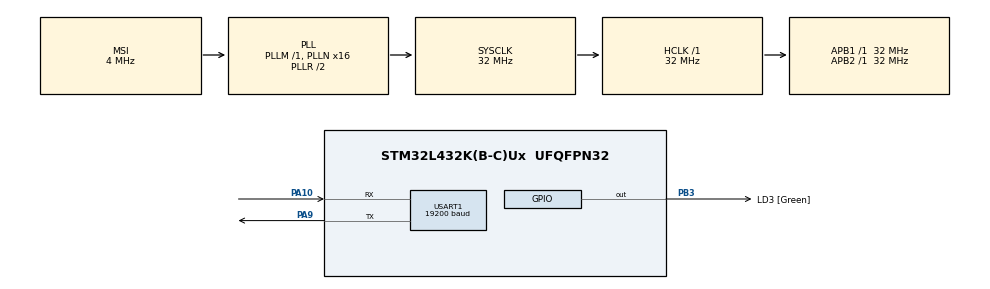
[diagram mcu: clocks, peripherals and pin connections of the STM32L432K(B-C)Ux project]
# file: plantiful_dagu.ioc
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Mcu.Family=STM32L4
Mcu.Name=STM32L432K(B-C)Ux
Mcu.Package=UFQFPN32
NVIC.PriorityGroup=NVIC_PRIORITYGROUP_4
PA0.GPIO_Label=MCO [High speed clock in]
PA0.Mode=HSE-External-Clock-Source-for-LittleOrca
PA0.Signal=RCC_CK_IN
PA10.Mode=Asynchronous
PA10.Signal=USART1_RX
PA13\ (JTMS-SWDIO).GPIO_Label=SWDIO
PA13\ (JTMS-SWDIO).Mode=Serial_Wire
PA13\ (JTMS-SWDIO).Signal=SYS_JTMS-SWDIO
PA14\ (JTCK-SWCLK).GPIO_Label=SWCLK
PA14\ (JTCK-SWCLK).Mode=Serial_Wire
PA14\ (JTCK-SWCLK).Signal=SYS_JTCK-SWCLK
PA15\ (JTDI).GPIO_Label=VCP_RX
PA15\ (JTDI).Signal=USART2_RX
PA2.GPIO_Label=VCP_TX
PA2.Signal=USART2_TX
PA9.Mode=Asynchronous
PA9.Signal=USART1_TX
PB3\ (JTDO-TRACESWO).GPIO_Label=LD3 [Green]
PB3\ (JTDO-TRACESWO).Signal=GPIO_Output
PC14-OSC32_IN\ (PC14).Mode=LSE-External-Oscillator
PC14-OSC32_IN\ (PC14).Signal=RCC_OSC32_IN
PC15-OSC32_OUT\ (PC15).Mode=LSE-External-Oscillator
PC15-OSC32_OUT\ (PC15).Signal=RCC_OSC32_OUT
ProjectManager.HeapSize=0x200
ProjectManager.StackSize=0x400
ProjectManager.TargetToolchain=MDK-ARM V5.27
RCC.AHBFreq_Value=32000000
RCC.APB1Freq_Value=32000000
RCC.APB1TimFreq_Value=32000000
RCC.APB2Freq_Value=32000000
RCC.APB2TimFreq_Value=32000000
RCC.CortexFreq_Value=32000000
RCC.HCLKFreq_Value=32000000
RCC.HSE_VALUE=8000000
RCC.HSI16_VALUE=16000000
RCC.HSI48_VALUE=48000000
RCC.HSI_VALUE=16000000
RCC.MSI_VALUE=4000000
RCC.PLLMUL=RCC_PLLMUL_4
RCC.PLLN=16
RCC.SYSCLKFreq_VALUE=32000000
RCC.SYSCLKSource=RCC_SYSCLKSOURCE_PLLCLK
RCC.VCOOutputFreq_Value=64000000
USART1.BaudRate=19200
USART1.VirtualMode-Asynchronous=VM_ASYNC
board=NUCLEO-L432KC

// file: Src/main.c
/* USER CODE BEGIN Header */
/**
  ******************************************************************************
  * @file           : main.c
  * @brief          : Main program body
  ******************************************************************************
  * @attention
  *
  * <h2><center>&copy; Copyright (c) 2021 STMicroelectronics.
  * All rights reserved.</center></h2>
  *
  * This software component is licensed by ST under BSD 3-Clause license,
  * the "License"; You may not use this file except in compliance with the
  * License. You may obtain a copy of the License at:
  *                        opensource.org/licenses/BSD-3-Clause
  *
  ******************************************************************************
  */
/* USER CODE END Header */

#include "main.h"

UART_HandleTypeDef huart1;

/* USER CODE BEGIN PV */
char buff[2];
int moveTime = 1000;
int stopTime = 50000;
/* USER CODE END PV */

void SystemClock_Config(void);
static void MX_GPIO_Init(void);
static void MX_USART1_UART_Init(void);

/* USER CODE BEGIN 0 */

void forward(void)
{
		/* Forward */
		buff[1] = 0x40; /* Set speed to be 50% of max (1.5 km/h) */
		buff[0] = 0xC2;
		HAL_UART_Transmit(&huart1, (uint8_t *) buff, sizeof(buff), 200);

		buff[1] = 0x40;
		buff[0] = 0xCA;
		HAL_UART_Transmit(&huart1, (uint8_t *) buff, sizeof(buff), 200);

		//HAL_Delay(500); /* Delay to move forward for a set time */
}

void backwards(void)
{
	  /*  Backwards */
		buff[1] = 0x40; /* Set speed to be 50% of max (1.5 km/h) */
		buff[0] = 0xC1;
		HAL_UART_Transmit(&huart1, (uint8_t *) buff, sizeof(buff), 200);

		buff[0] = 0xC9;
		HAL_UART_Transmit(&huart1, (uint8_t *) buff, sizeof(buff), 200);

		//HAL_Delay(500); /* Delay to move forward for a set time */
}

void right(void)
{
		/* Turn Right */
		buff[1] = 0x40;
		buff[0] = 0xC2;
		HAL_UART_Transmit(&huart1, (uint8_t *) buff, sizeof(buff), 200);

		//buff[1] = 0x06;
		//buff[0] = 0xCA;
		buff[1] = 0x40;
		buff[0] = 0xC9;
		HAL_UART_Transmit(&huart1, (uint8_t *) buff, sizeof(buff), 200);

		HAL_Delay(550); // we found that the left motor was weaker -> the same delay made it turn less degrees -> increase delay to account for weaker motor

}

void brake(void)
{
	  /* Brake */
		buff[1] = 0x00;
		buff[0] = 0xC0;
		HAL_UART_Transmit(&huart1, (uint8_t *) buff, sizeof(buff), 200);
		buff[0] = 0xC8;
		HAL_UART_Transmit(&huart1, (uint8_t *) buff, sizeof(buff), 200);

		HAL_Delay(5);

}

void turn(void)
{
	/* Turning right */

	buff[1] = 0x40; //50% power
	buff[0] = 0xC2;	//left wheel
	HAL_UART_Transmit(&huart1, (uint8_t *) buff, sizeof(buff), 200);

	buff[1] = 0x20;	//25% power
	buff[0] = 0xC9;	//right wheel
	HAL_UART_Transmit(&huart1, (uint8_t *) buff, sizeof(buff), 200);

	/* These seconds with these speeds, make it turn 180 degrees */
	HAL_Delay(1350);
	brake();

	/* Turning left
	buff[1] = 0x28;
	buff[0] = 0xC1;
	HAL_UART_Transmit(&huart1, (uint8_t *) buff, sizeof(buff), 200);

	buff[1] = 0x40;
	buff[0] = 0xCA;
	HAL_UART_Transmit(&huart1, (uint8_t *) buff, sizeof(buff), 200);

	HAL_Delay(900);*/
}

/* USER CODE END 0 */

int main(void)
{

  /* MCU Configuration--------------------------------------------------------*/

  /* Reset of all peripherals, Initializes the Flash interface and the Systick. */
  HAL_Init();

  /* Configure the system clock */
  SystemClock_Config();

  /* Initialize all configured peripherals */
  MX_GPIO_Init();
  MX_USART1_UART_Init();

  /* Infinite loop */
  while (1)
  {
    /* USER CODE BEGIN 3 */

		/* Capture plants for this day */
		for (int row = 0; row < 2; row++) {

			for(int plant = 0; plant < 5; plant++) {
				forward(); 									/* set car direction to forward */
				HAL_Delay(moveTime);				/* move car for time traveled between pots */
				brake();										/* stop car */
				HAL_Delay(stopTime);				/* pause car for capturing time */
			}

			turn();												/* turn to face the other row */
			HAL_Delay(1000);
		}

		/* Wait for 24 hours = 86400000 ms */
		for (int del = 0; del < 8; del++) {
			HAL_Delay(10000000);
		}
		HAL_Delay(6400000);

  } /* end while */
  /* USER CODE END 3 */
}

void SystemClock_Config(void)
{
  RCC_OscInitTypeDef RCC_OscInitStruct = {0};
  RCC_ClkInitTypeDef RCC_ClkInitStruct = {0};
  RCC_PeriphCLKInitTypeDef PeriphClkInit = {0};

  /** Configure LSE Drive Capability
  */
  HAL_PWR_EnableBkUpAccess();
  __HAL_RCC_LSEDRIVE_CONFIG(RCC_LSEDRIVE_LOW);
  /** Initializes the CPU, AHB and APB busses clocks
  */
  RCC_OscInitStruct.OscillatorType = RCC_OSCILLATORTYPE_LSE|RCC_OSCILLATORTYPE_MSI;
  RCC_OscInitStruct.LSEState = RCC_LSE_ON;
  RCC_OscInitStruct.MSIState = RCC_MSI_ON;
  RCC_OscInitStruct.MSICalibrationValue = 0;
  RCC_OscInitStruct.MSIClockRange = RCC_MSIRANGE_6;
  RCC_OscInitStruct.PLL.PLLState = RCC_PLL_ON;
  RCC_OscInitStruct.PLL.PLLSource = RCC_PLLSOURCE_MSI;
  RCC_OscInitStruct.PLL.PLLM = 1;
  RCC_OscInitStruct.PLL.PLLN = 16;
  RCC_OscInitStruct.PLL.PLLP = RCC_PLLP_DIV7;
  RCC_OscInitStruct.PLL.PLLQ = RCC_PLLQ_DIV2;
  RCC_OscInitStruct.PLL.PLLR = RCC_PLLR_DIV2;
  if (HAL_RCC_OscConfig(&RCC_OscInitStruct) != HAL_OK)
  {
    Error_Handler();
  }
  /** Initializes the CPU, AHB and APB busses clocks
  */
  RCC_ClkInitStruct.ClockType = RCC_CLOCKTYPE_HCLK|RCC_CLOCKTYPE_SYSCLK
                              |RCC_CLOCKTYPE_PCLK1|RCC_CLOCKTYPE_PCLK2;
  RCC_ClkInitStruct.SYSCLKSource = RCC_SYSCLKSOURCE_PLLCLK;
  RCC_ClkInitStruct.AHBCLKDivider = RCC_SYSCLK_DIV1;
  RCC_ClkInitStruct.APB1CLKDivider = RCC_HCLK_DIV1;
  RCC_ClkInitStruct.APB2CLKDivider = RCC_HCLK_DIV1;

  if (HAL_RCC_ClockConfig(&RCC_ClkInitStruct, FLASH_LATENCY_1) != HAL_OK)
  {
    Error_Handler();
  }
  PeriphClkInit.PeriphClockSelection = RCC_PERIPHCLK_USART1;
  PeriphClkInit.Usart1ClockSelection = RCC_USART1CLKSOURCE_PCLK2;
  if (HAL_RCCEx_PeriphCLKConfig(&PeriphClkInit) != HAL_OK)
  {
    Error_Handler();
  }
  /** Configure the main internal regulator output voltage
  */
  if (HAL_PWREx_ControlVoltageScaling(PWR_REGULATOR_VOLTAGE_SCALE1) != HAL_OK)
  {
    Error_Handler();
  }
  /** Enable MSI Auto calibration
  */
  HAL_RCCEx_EnableMSIPLLMode();
}

static void MX_USART1_UART_Init(void)
{

  huart1.Instance = USART1;
  huart1.Init.BaudRate = 19200;
  huart1.Init.WordLength = UART_WORDLENGTH_8B;
  huart1.Init.StopBits = UART_STOPBITS_1;
  huart1.Init.Parity = UART_PARITY_NONE;
  huart1.Init.Mode = UART_MODE_TX_RX;
  huart1.Init.HwFlowCtl = UART_HWCONTROL_NONE;
  huart1.Init.OverSampling = UART_OVERSAMPLING_16;
  huart1.Init.OneBitSampling = UART_ONE_BIT_SAMPLE_DISABLE;
  huart1.AdvancedInit.AdvFeatureInit = UART_ADVFEATURE_NO_INIT;
  if (HAL_UART_Init(&huart1) != HAL_OK)
  {
    Error_Handler();
  }

}

static void MX_GPIO_Init(void)
{
  GPIO_InitTypeDef GPIO_InitStruct = {0};

  /* GPIO Ports Clock Enable */
  __HAL_RCC_GPIOC_CLK_ENABLE();
  __HAL_RCC_GPIOA_CLK_ENABLE();
  __HAL_RCC_GPIOB_CLK_ENABLE();

  /*Configure GPIO pin Output Level */
  HAL_GPIO_WritePin(LD3_GPIO_Port, LD3_Pin, GPIO_PIN_RESET);

  /*Configure GPIO pin : VCP_TX_Pin */
  GPIO_InitStruct.Pin = VCP_TX_Pin;
  GPIO_InitStruct.Mode = GPIO_MODE_AF_PP;
  GPIO_InitStruct.Pull = GPIO_NOPULL;
  GPIO_InitStruct.Speed = GPIO_SPEED_FREQ_VERY_HIGH;
  GPIO_InitStruct.Alternate = GPIO_AF7_USART2;
  HAL_GPIO_Init(VCP_TX_GPIO_Port, &GPIO_InitStruct);

  /*Configure GPIO pin : VCP_RX_Pin */
  GPIO_InitStruct.Pin = VCP_RX_Pin;
  GPIO_InitStruct.Mode = GPIO_MODE_AF_PP;
  GPIO_InitStruct.Pull = GPIO_NOPULL;
  GPIO_InitStruct.Speed = GPIO_SPEED_FREQ_VERY_HIGH;
  GPIO_InitStruct.Alternate = GPIO_AF3_USART2;
  HAL_GPIO_Init(VCP_RX_GPIO_Port, &GPIO_InitStruct);

  /*Configure GPIO pin : LD3_Pin */
  GPIO_InitStruct.Pin = LD3_Pin;
  GPIO_InitStruct.Mode = GPIO_MODE_OUTPUT_PP;
  GPIO_InitStruct.Pull = GPIO_NOPULL;
  GPIO_InitStruct.Speed = GPIO_SPEED_FREQ_LOW;
  HAL_GPIO_Init(LD3_GPIO_Port, &GPIO_InitStruct);

}

void Error_Handler(void)
{
}

/************************ (C) COPYRIGHT STMicroelectronics *****END OF FILE****/
